AUTOSAR XML (schema 00047)
package /Components
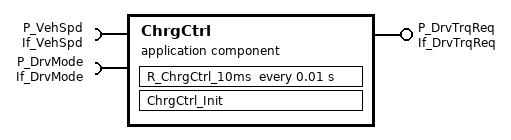
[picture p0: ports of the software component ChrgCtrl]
  application sw component type ChrgCtrl
    require port P_VehSpd: nonqueued-receiver-com-spec{data-element=In_VehSpd, init-value=0}, required-interface=If_VehSpd
    require port P_DrvMode: nonqueued-receiver-com-spec{data-element=In_DrvMode, init-value=ECO}, required-interface=If_DrvMode
    provide port P_DrvTrqReq: nonqueued-sender-com-spec{data-element=Out_DrvTrqReq, init-value=0}, provided-interface=If_DrvTrqReq
    behavior ChrgCtrl_IB: handle-termination-and-restart=NO-SUPPORT, supports-multiple-instantiation=true
      ar-typed-per-instance-memorys:
        data ChrgCtrl_Irv_TrqLim: category=VALUE, sw-calibration-access=READ-ONLY, type=Float
      timing event Event_R_ChrgCtrl_10ms: start-on-event=R_ChrgCtrl_10ms, period=0.01
      runnable ChrgCtrl_Init
      runnable R_ChrgCtrl_10ms: symbol=ChrgCtrl_Step
        data-read-access:
          access IN_P_DrvMode_In_DrvMode: accessed-variable=P_DrvMode.In_DrvMode
          access IN_P_VehSpd_In_VehSpd: accessed-variable=P_VehSpd.In_VehSpd
        data-write-access:
          access OUT_P_DrvTrqReq_Out_DrvTrqReq: accessed-variable=P_DrvTrqReq.Out_DrvTrqReq
        parameter access SCALPRM_Cal_TrqMax: accessed-parameter=Cal_TrqMax
      shared-parameters:
        parameter data prototype Cal_TrqMax: category=VALUE, sw-calibration-access=READ-WRITE, type=Float, init-value=constant-reference={short-label=Cal_TrqMax, constant=Cal_TrqMax}
